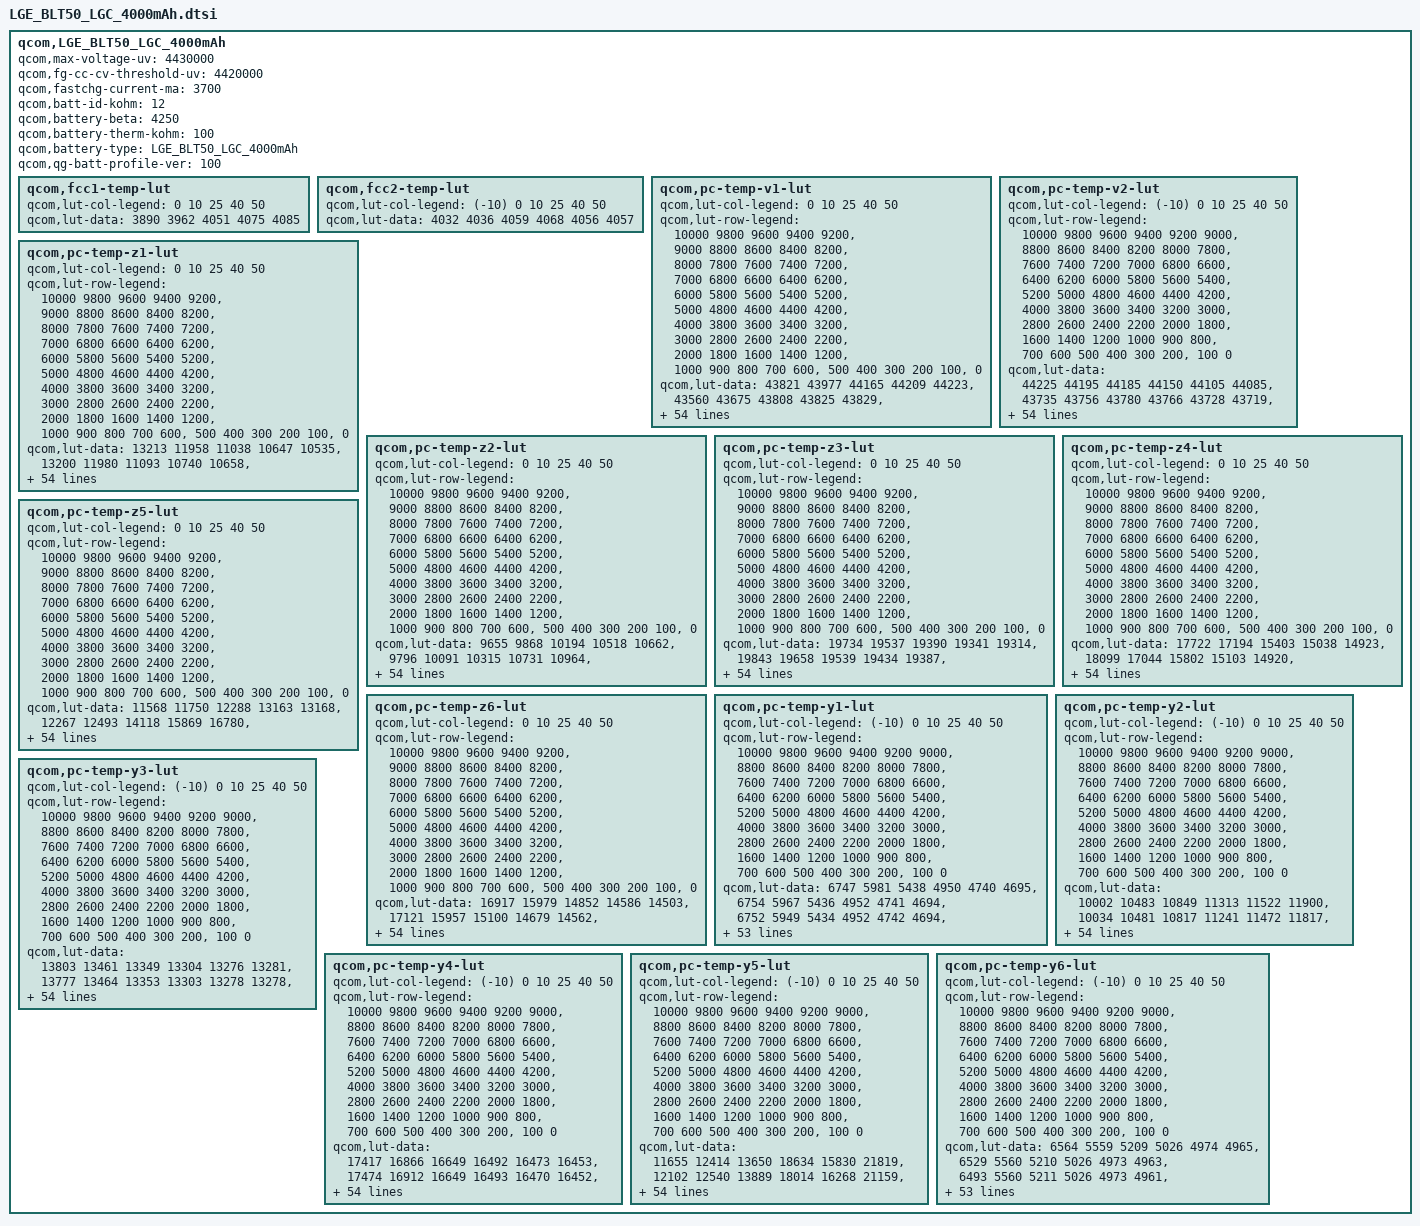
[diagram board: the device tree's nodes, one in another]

qcom,LGE_BLT50_LGC_4000mAh {
    /* 4551784_LGE_BLT50lgc_4000mAh_averaged_MasterSlave_Jun10th2020 */
    qcom,max-voltage-uv = <4430000>;
    qcom,fg-cc-cv-threshold-uv = <4420000>;
    qcom,fastchg-current-ma = <3700>;
    qcom,batt-id-kohm = <12>;
    qcom,battery-beta = <4250>;
    qcom,battery-therm-kohm = <100>;
    qcom,battery-type = "LGE_BLT50_LGC_4000mAh";
    qcom,qg-batt-profile-ver = <100>;

	qcom,fcc1-temp-lut {
		qcom,lut-col-legend = <0 10 25 40 50>;
		qcom,lut-data = <3890 3962 4051 4075 4085>;
	};

	qcom,fcc2-temp-lut {
		qcom,lut-col-legend = <(-10) 0 10 25 40 50>;
		qcom,lut-data = <4032 4036 4059 4068 4056 4057>;
	};

	qcom,pc-temp-v1-lut {
		qcom,lut-col-legend = <0 10 25 40 50>;
		qcom,lut-row-legend = <10000 9800 9600 9400 9200>,
			<9000 8800 8600 8400 8200>,
			<8000 7800 7600 7400 7200>,
			<7000 6800 6600 6400 6200>,
			<6000 5800 5600 5400 5200>,
			<5000 4800 4600 4400 4200>,
			<4000 3800 3600 3400 3200>,
			<3000 2800 2600 2400 2200>,
			<2000 1800 1600 1400 1200>,
			<1000 900 800 700 600>,
			<500 400 300 200 100>,
			<0>;
		qcom,lut-data = <43821 43977 44165 44209 44223>,
			<43560 43675 43808 43825 43829>,
			<43296 43394 43532 43538 43533>,
			<43028 43138 43284 43284 43279>,
			<42769 42897 43034 43037 43032>,
			<42517 42657 42794 42801 42799>,
			<42274 42417 42554 42567 42568>,
			<42040 42182 42313 42328 42333>,
			<41816 41953 42076 42092 42099>,
			<41598 41728 41842 41859 41866>,
			<41385 41510 41613 41629 41635>,
			<41177 41297 41391 41404 41409>,
			<40973 41088 41174 41182 41188>,
			<40774 40885 40965 40966 40973>,
			<40579 40686 40758 40759 40763>,
			<40387 40494 40557 40559 40560>,
			<40200 40307 40366 40367 40365>,
			<40028 40130 40184 40183 40180>,
			<39868 39966 40011 40007 40002>,
			<39719 39813 39851 39844 39837>,
			<39579 39664 39698 39689 39679>,
			<39446 39520 39549 39525 39512>,
			<39320 39381 39408 39352 39334>,
			<39197 39244 39243 39173 39153>,
			<39081 39110 38997 38971 38966>,
			<38971 38975 38756 38774 38783>,
			<38867 38833 38624 38643 38644>,
			<38770 38696 38535 38551 38538>,
			<38679 38572 38461 38467 38444>,
			<38594 38458 38396 38377 38352>,
			<38517 38370 38338 38293 38269>,
			<38445 38305 38279 38221 38195>,
			<38382 38253 38222 38158 38126>,
			<38325 38205 38169 38101 38065>,
			<38276 38164 38120 38052 38014>,
			<38234 38125 38074 38006 37965>,
			<38200 38090 38031 37955 37903>,
			<38163 38053 37990 37901 37830>,
			<38117 38004 37935 37836 37755>,
			<38059 37937 37854 37754 37680>,
			<37980 37854 37755 37658 37598>,
			<37849 37735 37641 37547 37489>,
			<37708 37592 37506 37415 37354>,
			<37575 37429 37346 37252 37188>,
			<37413 37278 37192 37099 37033>,
			<37270 37162 37086 37002 36942>,
			<37217 37134 37064 36980 36922>,
			<37172 37104 37042 36967 36908>,
			<37129 37077 37025 36951 36892>,
			<37081 37037 36996 36914 36851>,
			<36961 36901 36818 36708 36619>,
			<36588 36480 36406 36286 36191>,
			<35999 35902 35836 35714 35617>,
			<35199 35106 35053 34932 34834>,
			<33882 33815 33842 33728 33631>,
			<30000 30000 30000 30000 30000>;
	};

	qcom,pc-temp-v2-lut {
		qcom,lut-col-legend = <(-10) 0 10 25 40 50>;
		qcom,lut-row-legend = <10000 9800 9600 9400 9200 9000>,
			<8800 8600 8400 8200 8000 7800>,
			<7600 7400 7200 7000 6800 6600>,
			<6400 6200 6000 5800 5600 5400>,
			<5200 5000 4800 4600 4400 4200>,
			<4000 3800 3600 3400 3200 3000>,
			<2800 2600 2400 2200 2000 1800>,
			<1600 1400 1200 1000 900 800>,
			<700 600 500 400 300 200>,
			<100 0>;
		qcom,lut-data = <44225 44195 44185 44150 44105 44085>,
			<43735 43756 43780 43766 43728 43719>,
			<43316 43376 43426 43428 43395 43393>,
			<42983 43067 43131 43146 43115 43115>,
			<42716 42815 42887 42909 42879 42878>,
			<42464 42573 42650 42678 42650 42647>,
			<42210 42324 42405 42441 42414 42411>,
			<41960 42080 42163 42204 42180 42178>,
			<41700 41841 41927 41971 41948 41948>,
			<41431 41605 41694 41740 41719 41719>,
			<41178 41373 41466 41512 41493 41494>,
			<40959 41144 41244 41291 41271 41273>,
			<40748 40919 41026 41073 41053 41056>,
			<40521 40695 40816 40861 40844 40846>,
			<40281 40473 40611 40653 40641 40640>,
			<40047 40253 40401 40452 40443 40442>,
			<39820 40029 40185 40255 40249 40250>,
			<39604 39811 39968 40068 40062 40065>,
			<39400 39610 39755 39898 39889 39891>,
			<39205 39421 39545 39739 39725 39724>,
			<39029 39243 39349 39553 39555 39555>,
			<38881 39076 39165 39321 39375 39386>,
			<38736 38920 38996 39095 39190 39210>,
			<38549 38775 38843 38910 38988 39007>,
			<38330 38638 38702 38746 38780 38792>,
			<38179 38509 38573 38607 38621 38631>,
			<38093 38388 38455 38488 38503 38513>,
			<38026 38270 38347 38383 38401 38410>,
			<37959 38142 38249 38287 38307 38314>,
			<37897 38010 38157 38198 38221 38224>,
			<37837 37918 38067 38117 38143 38143>,
			<37777 37860 37976 38042 38070 38068>,
			<37718 37809 37895 37973 38000 37998>,
			<37656 37750 37826 37912 37933 37936>,
			<37595 37690 37767 37854 37867 37875>,
			<37534 37631 37717 37790 37793 37792>,
			<37474 37572 37675 37723 37712 37681>,
			<37413 37511 37629 37652 37626 37571>,
			<37348 37445 37569 37578 37536 37475>,
			<37279 37375 37498 37498 37442 37383>,
			<37212 37300 37418 37408 37350 37292>,
			<37144 37217 37323 37304 37258 37202>,
			<37067 37131 37196 37178 37141 37085>,
			<36976 37042 37051 37031 36997 36940>,
			<36874 36948 36935 36898 36857 36802>,
			<36692 36832 36845 36860 36829 36778>,
			<36615 36776 36813 36843 36817 36768>,
			<36508 36716 36771 36817 36798 36749>,
			<36357 36647 36700 36767 36761 36708>,
			<36151 36556 36565 36597 36643 36574>,
			<35839 36348 36296 36190 36295 36215>,
			<35354 35914 35809 35622 35778 35698>,
			<34586 35229 35127 34895 35133 35070>,
			<33393 34245 34106 33962 34380 34341>,
			<32071 32838 32822 32949 33297 33236>,
			<29691 29740 29526 29524 29521 29521>;
	};

	qcom,pc-temp-z1-lut {
		qcom,lut-col-legend = <0 10 25 40 50>;
		qcom,lut-row-legend = <10000 9800 9600 9400 9200>,
			<9000 8800 8600 8400 8200>,
			<8000 7800 7600 7400 7200>,
			<7000 6800 6600 6400 6200>,
			<6000 5800 5600 5400 5200>,
			<5000 4800 4600 4400 4200>,
			<4000 3800 3600 3400 3200>,
			<3000 2800 2600 2400 2200>,
			<2000 1800 1600 1400 1200>,
			<1000 900 800 700 600>,
			<500 400 300 200 100>,
			<0>;
		qcom,lut-data = <13213 11958 11038 10647 10535>,
			<13200 11980 11093 10740 10658>,
			<13194 11997 11110 10749 10665>,
			<13190 12008 11116 10754 10669>,
			<13192 12015 11111 10756 10671>,
			<13215 12014 11100 10755 10673>,
			<13238 11998 11096 10753 10673>,
			<13230 11982 11096 10752 10672>,
			<13194 11974 11096 10751 10672>,
			<13153 11966 11096 10750 10671>,
			<13099 11956 11096 10749 10671>,
			<13037 11941 11096 10749 10671>,
			<12999 11928 11097 10749 10671>,
			<12975 11924 11097 10748 10672>,
			<12950 11924 11096 10748 10672>,
			<12909 11926 11094 10748 10673>,
			<12861 11937 11094 10748 10674>,
			<12829 11950 11098 10750 10674>,
			<12807 11963 11102 10753 10675>,
			<12790 11979 11105 10756 10676>,
			<12777 11986 11107 10758 10678>,
			<12765 11988 11111 10759 10679>,
			<12759 11989 11116 10760 10680>,
			<12756 11994 11120 10761 10680>,
			<12756 12004 11121 10762 10682>,
			<12763 12014 11123 10764 10683>,
			<12776 12026 11126 10766 10685>,
			<12787 12037 11131 10769 10688>,
			<12793 12045 11137 10772 10690>,
			<12799 12051 11144 10775 10692>,
			<12806 12056 11150 10778 10694>,
			<12816 12064 11154 10781 10696>,
			<12827 12070 11157 10782 10697>,
			<12846 12072 11161 10784 10699>,
			<12868 12079 11169 10786 10701>,
			<12883 12087 11178 10789 10702>,
			<12893 12099 11187 10793 10704>,
			<12900 12115 11196 10799 10706>,
			<12902 12133 11203 10803 10708>,
			<12905 12154 11210 10805 10709>,
			<12918 12166 11216 10807 10710>,
			<12978 12171 11220 10809 10712>,
			<13013 12175 11224 10811 10714>,
			<12996 12188 11231 10812 10715>,
			<13033 12195 11239 10814 10717>,
			<12981 12184 11247 10816 10718>,
			<12988 12195 11248 10816 10719>,
			<13022 12209 11246 10816 10719>,
			<12977 12202 11251 10818 10720>,
			<12997 12191 11259 10820 10722>,
			<12988 12210 11265 10824 10725>,
			<12993 12226 11278 10830 10729>,
			<13009 12256 11307 10839 10735>,
			<13048 12265 11334 10851 10745>,
			<13048 12265 11334 10851 10745>,
			<13048 12265 11334 10851 10745>;
	};

	qcom,pc-temp-z2-lut {
		qcom,lut-col-legend = <0 10 25 40 50>;
		qcom,lut-row-legend = <10000 9800 9600 9400 9200>,
			<9000 8800 8600 8400 8200>,
			<8000 7800 7600 7400 7200>,
			<7000 6800 6600 6400 6200>,
			<6000 5800 5600 5400 5200>,
			<5000 4800 4600 4400 4200>,
			<4000 3800 3600 3400 3200>,
			<3000 2800 2600 2400 2200>,
			<2000 1800 1600 1400 1200>,
			<1000 900 800 700 600>,
			<500 400 300 200 100>,
			<0>;
		qcom,lut-data = <9655 9868 10194 10518 10662>,
			<9796 10091 10315 10731 10964>,
			<9837 10205 10326 10705 10976>,
			<9863 10199 10330 10655 10942>,
			<9887 10183 10317 10616 10925>,
			<9916 10171 10289 10579 10916>,
			<9944 10156 10282 10565 10912>,
			<9960 10142 10286 10595 10927>,
			<9973 10130 10289 10637 10947>,
			<9977 10120 10268 10656 10926>,
			<9977 10114 10232 10668 10827>,
			<9977 10112 10245 10672 10777>,
			<9976 10109 10387 10638 10814>,
			<9974 10104 10515 10605 10864>,
			<9973 10095 10562 10608 10885>,
			<9974 10084 10601 10616 10900>,
			<9976 10071 10639 10620 10919>,
			<9976 10057 10680 10627 10949>,
			<9974 10044 10704 10636 10976>,
			<9971 10031 10608 10656 10988>,
			<9971 10028 10464 10691 10996>,
			<9971 10032 10456 10752 11029>,
			<9969 10039 10483 10895 11210>,
			<9961 10050 10500 10987 11350>,
			<9950 10072 10505 10870 11250>,
			<9943 10096 10508 10678 11062>,
			<9938 10123 10508 10665 11047>,
			<9935 10149 10504 10782 11229>,
			<9935 10167 10505 10852 11350>,
			<9936 10181 10529 10839 11222>,
			<9939 10192 10558 10820 11021>,
			<9950 10200 10566 10814 10971>,
			<9963 10207 10571 10812 10980>,
			<9974 10215 10572 10815 11001>,
			<9983 10223 10567 10867 11043>,
			<9960 10233 10561 10946 11115>,
			<9758 10246 10568 11008 11248>,
			<9566 10262 10588 11067 11471>,
			<9512 10279 10610 11115 11552>,
			<9479 10301 10635 11160 11467>,
			<9497 10320 10659 11188 11380>,
			<9847 10334 10679 11184 11387>,
			<10012 10350 10696 11176 11414>,
			<9632 10370 10707 11204 11436>,
			<9499 10505 10765 11216 11456>,
			<9405 10567 10837 11192 11491>,
			<9365 10485 10806 11150 11486>,
			<9297 10398 10790 11184 11510>,
			<9303 10452 10782 11175 11562>,
			<9314 10498 10798 11254 11663>,
			<9312 10522 10927 11233 11257>,
			<9300 10370 10813 11041 11080>,
			<9343 10170 10748 10894 10983>,
			<9389 10001 10656 10777 10918>,
			<9389 10001 10656 10777 10918>,
			<9389 10001 10656 10777 10918>;
	};

	qcom,pc-temp-z3-lut {
		qcom,lut-col-legend = <0 10 25 40 50>;
		qcom,lut-row-legend = <10000 9800 9600 9400 9200>,
			<9000 8800 8600 8400 8200>,
			<8000 7800 7600 7400 7200>,
			<7000 6800 6600 6400 6200>,
			<6000 5800 5600 5400 5200>,
			<5000 4800 4600 4400 4200>,
			<4000 3800 3600 3400 3200>,
			<3000 2800 2600 2400 2200>,
			<2000 1800 1600 1400 1200>,
			<1000 900 800 700 600>,
			<500 400 300 200 100>,
			<0>;
		qcom,lut-data = <19734 19537 19390 19341 19314>,
			<19843 19658 19539 19434 19387>,
			<19906 19718 19587 19456 19412>,
			<19951 19708 19605 19468 19423>,
			<19976 19684 19605 19467 19423>,
			<19993 19673 19602 19459 19412>,
			<20003 19668 19597 19448 19399>,
			<20002 19663 19579 19435 19388>,
			<19997 19655 19558 19421 19377>,
			<19989 19646 19540 19408 19367>,
			<19978 19636 19524 19395 19358>,
			<19962 19624 19516 19385 19349>,
			<19948 19615 19513 19378 19340>,
			<19933 19613 19511 19372 19333>,
			<19919 19612 19504 19363 19330>,
			<19906 19612 19495 19354 19328>,
			<19893 19613 19489 19350 19326>,
			<19880 19616 19485 19349 19322>,
			<19865 19618 19479 19348 19319>,
			<19851 19619 19465 19348 19319>,
			<19835 19620 19448 19347 19319>,
			<19820 19623 19445 19350 19321>,
			<19808 19626 19443 19364 19332>,
			<19800 19628 19443 19375 19341>,
			<19793 19631 19454 19368 19331>,
			<19785 19634 19466 19356 19313>,
			<19778 19643 19465 19348 19314>,
			<19771 19650 19457 19341 19342>,
			<19765 19651 19448 19339 19361>,
			<19759 19649 19441 19360 19360>,
			<19754 19647 19435 19389 19359>,
			<19750 19639 19437 19391 19356>,
			<19744 19627 19443 19381 19349>,
			<19733 19618 19447 19373 19342>,
			<19713 19609 19449 19366 19336>,
			<19678 19600 19450 19361 19332>,
			<19591 19592 19448 19360 19333>,
			<19509 19584 19443 19361 19336>,
			<19469 19578 19438 19360 19337>,
			<19440 19573 19432 19360 19334>,
			<19446 19568 19428 19358 19329>,
			<19634 19561 19428 19353 19324>,
			<19726 19553 19427 19347 19319>,
			<19555 19544 19420 19345 19318>,
			<19427 19498 19403 19339 19318>,
			<19350 19470 19392 19332 19313>,
			<19338 19407 19382 19333 19311>,
			<19297 19367 19381 19325 19308>,
			<19295 19329 19365 19323 19305>,
			<19292 19321 19348 19319 19304>,
			<19291 19326 19366 19329 19326>,
			<19297 19365 19355 19339 19331>,
			<19357 19366 19372 19347 19333>,
			<19445 19370 19400 19349 19332>,
			<19445 19370 19400 19349 19332>,
			<19445 19370 19400 19349 19332>;
	};

	qcom,pc-temp-z4-lut {
		qcom,lut-col-legend = <0 10 25 40 50>;
		qcom,lut-row-legend = <10000 9800 9600 9400 9200>,
			<9000 8800 8600 8400 8200>,
			<8000 7800 7600 7400 7200>,
			<7000 6800 6600 6400 6200>,
			<6000 5800 5600 5400 5200>,
			<5000 4800 4600 4400 4200>,
			<4000 3800 3600 3400 3200>,
			<3000 2800 2600 2400 2200>,
			<2000 1800 1600 1400 1200>,
			<1000 900 800 700 600>,
			<500 400 300 200 100>,
			<0>;
		qcom,lut-data = <17722 17194 15403 15038 14923>,
			<18099 17044 15802 15103 14920>,
			<17934 16831 15540 15039 14898>,
			<17431 16511 15250 14929 14836>,
			<16982 16116 15117 14868 14797>,
			<16614 15834 15021 14826 14771>,
			<16292 15630 14946 14800 14757>,
			<16053 15472 14880 14785 14751>,
			<15859 15355 14837 14775 14748>,
			<15704 15262 14819 14767 14745>,
			<15577 15186 14807 14762 14741>,
			<15473 15121 14789 14756 14737>,
			<15390 15070 14759 14747 14732>,
			<15322 15034 14735 14739 14726>,
			<15267 15006 14724 14733 14719>,
			<15224 14982 14715 14728 14708>,
			<15187 14960 14708 14722 14700>,
			<15156 14939 14700 14713 14693>,
			<15127 14916 14695 14705 14688>,
			<15103 14892 14701 14698 14682>,
			<15083 14870 14713 14692 14676>,
			<15066 14848 14714 14691 14675>,
			<15061 14829 14712 14695 14683>,
			<15062 14815 14713 14702 14699>,
			<15065 14803 14774 14751 14744>,
			<15067 14799 14848 14823 14808>,
			<15068 14802 14855 14835 14816>,
			<15069 14807 14850 14826 14773>,
			<15070 14817 14844 14811 14733>,
			<15071 14832 14829 14768 14712>,
			<15070 14839 14809 14717 14697>,
			<15069 14836 14787 14701 14687>,
			<15068 14832 14762 14694 14680>,
			<15071 14826 14743 14690 14676>,
			<15080 14819 14729 14687 14674>,
			<15103 14811 14720 14685 14673>,
			<15197 14802 14718 14687 14680>,
			<15271 14793 14717 14695 14700>,
			<15272 14783 14718 14701 14708>,
			<15270 14771 14727 14705 14704>,
			<15244 14765 14736 14708 14698>,
			<14961 14763 14729 14705 14693>,
			<14820 14762 14719 14700 14687>,
			<14961 14749 14718 14699 14688>,
			<14959 14720 14707 14694 14684>,
			<14992 14706 14682 14676 14669>,
			<15002 14761 14676 14662 14656>,
			<15036 14799 14664 14651 14641>,
			<15029 14830 14668 14640 14629>,
			<15014 14831 14681 14643 14634>,
			<15004 14819 14681 14657 14630>,
			<15014 14801 14706 14649 14627>,
			<14998 14818 14691 14642 14627>,
			<14949 14837 14669 14643 14632>,
			<14949 14837 14669 14643 14632>,
			<14949 14837 14669 14643 14632>;
	};

	qcom,pc-temp-z5-lut {
		qcom,lut-col-legend = <0 10 25 40 50>;
		qcom,lut-row-legend = <10000 9800 9600 9400 9200>,
			<9000 8800 8600 8400 8200>,
			<8000 7800 7600 7400 7200>,
			<7000 6800 6600 6400 6200>,
			<6000 5800 5600 5400 5200>,
			<5000 4800 4600 4400 4200>,
			<4000 3800 3600 3400 3200>,
			<3000 2800 2600 2400 2200>,
			<2000 1800 1600 1400 1200>,
			<1000 900 800 700 600>,
			<500 400 300 200 100>,
			<0>;
		qcom,lut-data = <11568 11750 12288 13163 13168>,
			<12267 12493 14118 15869 16780>,
			<13157 13134 14945 16703 18566>,
			<14196 13657 15551 17917 19750>,
			<15242 14113 16152 18381 19943>,
			<16318 14575 16700 18624 19896>,
			<17358 15069 17392 18704 19806>,
			<18267 15486 18414 18631 19317>,
			<19094 15796 19024 18479 18529>,
			<19799 16043 19014 18187 17989>,
			<20400 16137 18982 17666 17554>,
			<20915 16164 19222 17400 17190>,
			<21337 16187 21028 17468 16819>,
			<21713 16196 22916 17584 16562>,
			<21990 16160 24050 17458 16661>,
			<22199 16162 25100 17125 17081>,
			<22369 16230 26189 17045 17426>,
			<22422 16349 27463 17575 17701>,
			<22418 16603 28311 18351 18016>,
			<22390 17113 26712 19022 18543>,
			<22249 17730 24245 19860 19618>,
			<21905 18773 24378 22024 21462>,
			<21485 20163 25489 29142 26167>,
			<20882 21709 27416 33936 29521>,
			<20222 23602 35382 30514 25633>,
			<19690 26084 43854 23953 18313>,
			<19209 30575 42415 20026 16769>,
			<18815 34601 34188 17169 17737>,
			<18491 35707 27956 16015 19066>,
			<18227 36285 24220 18947 20795>,
			<18053 36400 21985 23409 22923>,
			<17941 34455 22154 25372 24870>,
			<17787 31644 23300 26654 26818>,
			<17409 29977 24843 27692 28324>,
			<16761 28701 27729 28739 29590>,
			<15845 27887 30249 29599 30443>,
			<14142 27250 30982 30043 30401>,
			<12724 26791 31403 30363 29890>,
			<12230 27027 31350 30352 29049>,
			<11909 28229 29776 28486 26563>,
			<12431 29114 28422 26025 23713>,
			<20632 29334 28878 24498 22132>,
			<24459 29606 29603 23223 20955>,
			<15240 30918 27441 21794 19724>,
			<12933 29628 27083 21367 19834>,
			<12117 27026 28798 22359 20392>,
			<11868 17105 25255 24205 21493>,
			<11364 13980 25961 23459 23710>,
			<11335 12644 22767 25443 27461>,
			<11290 12453 17812 23814 24633>,
			<11304 12771 21051 20298 28116>,
			<11440 14133 17077 22407 31303>,
			<11982 13651 18916 25774 35034>,
			<12906 13423 23766 26648 33155>,
			<12906 13423 23766 26648 33155>,
			<12906 13423 23766 26648 33155>;
	};

	qcom,pc-temp-z6-lut {
		qcom,lut-col-legend = <0 10 25 40 50>;
		qcom,lut-row-legend = <10000 9800 9600 9400 9200>,
			<9000 8800 8600 8400 8200>,
			<8000 7800 7600 7400 7200>,
			<7000 6800 6600 6400 6200>,
			<6000 5800 5600 5400 5200>,
			<5000 4800 4600 4400 4200>,
			<4000 3800 3600 3400 3200>,
			<3000 2800 2600 2400 2200>,
			<2000 1800 1600 1400 1200>,
			<1000 900 800 700 600>,
			<500 400 300 200 100>,
			<0>;
		qcom,lut-data = <16917 15979 14852 14586 14503>,
			<17121 15957 15100 14679 14562>,
			<17055 15907 15012 14660 14561>,
			<16846 15781 14909 14625 14546>,
			<16652 15581 14852 14600 14531>,
			<16484 15441 14807 14578 14515>,
			<16332 15346 14767 14561 14502>,
			<16213 15270 14729 14547 14493>,
			<16115 15208 14700 14536 14486>,
			<16029 15157 14684 14525 14479>,
			<15952 15114 14671 14516 14473>,
			<15883 15076 14658 14507 14466>,
			<15823 15048 14645 14500 14459>,
			<15769 15032 14633 14492 14453>,
			<15722 15022 14623 14485 14447>,
			<15680 15014 14615 14478 14441>,
			<15643 15008 14609 14472 14436>,
			<15609 15004 14603 14468 14431>,
			<15577 14997 14599 14464 14427>,
			<15550 14991 14594 14461 14425>,
			<15528 14985 14590 14458 14422>,
			<15509 14979 14588 14459 14422>,
			<15503 14976 14587 14466 14431>,
			<15507 14975 14588 14477 14443>,
			<15513 14975 14620 14497 14460>,
			<15518 14975 14658 14519 14477>,
			<15523 14981 14661 14522 14480>,
			<15528 14991 14657 14516 14477>,
			<15533 14999 14651 14508 14471>,
			<15538 15007 14642 14502 14465>,
			<15543 15010 14631 14496 14457>,
			<15548 15006 14624 14489 14450>,
			<15551 15001 14617 14481 14443>,
			<15550 14996 14612 14475 14438>,
			<15548 14990 14609 14470 14433>,
			<15544 14985 14607 14467 14430>,
			<15533 14981 14605 14468 14433>,
			<15524 14977 14604 14471 14444>,
			<15525 14975 14604 14474 14448>,
			<15526 14974 14607 14476 14445>,
			<15530 14973 14609 14477 14440>,
			<15543 14973 14607 14474 14435>,
			<15549 14973 14603 14468 14430>,
			<15530 14967 14600 14467 14430>,
			<15473 14933 14588 14462 14428>,
			<15451 14916 14573 14450 14419>,
			<15451 14909 14567 14445 14413>,
			<15449 14906 14561 14436 14404>,
			<15446 14903 14556 14429 14398>,
			<15445 14904 14554 14430 14399>,
			<15451 14912 14565 14441 14410>,
			<15466 14935 14575 14445 14412>,
			<15501 14956 14584 14448 14415>,
			<15543 14988 14599 14452 14419>,
			<15543 14988 14599 14452 14419>,
			<15543 14988 14599 14452 14419>;
	};

	qcom,pc-temp-y1-lut {
		qcom,lut-col-legend = <(-10) 0 10 25 40 50>;
		qcom,lut-row-legend = <10000 9800 9600 9400 9200 9000>,
			<8800 8600 8400 8200 8000 7800>,
			<7600 7400 7200 7000 6800 6600>,
			<6400 6200 6000 5800 5600 5400>,
			<5200 5000 4800 4600 4400 4200>,
			<4000 3800 3600 3400 3200 3000>,
			<2800 2600 2400 2200 2000 1800>,
			<1600 1400 1200 1000 900 800>,
			<700 600 500 400 300 200>,
			<100 0>;
		qcom,lut-data = <6747 5981 5438 4950 4740 4695>,
			<6754 5967 5436 4952 4741 4694>,
			<6752 5949 5434 4952 4742 4694>,
			<6746 5931 5431 4951 4742 4693>,
			<6737 5918 5428 4949 4742 4693>,
			<6731 5913 5425 4947 4741 4692>,
			<6721 5915 5421 4943 4740 4692>,
			<6711 5918 5418 4940 4739 4692>,
			<6723 5921 5418 4937 4738 4691>,
			<6782 5925 5422 4935 4737 4690>,
			<6815 5928 5424 4933 4736 4690>,
			<6796 5929 5420 4931 4736 4689>,
			<6771 5930 5416 4929 4736 4689>,
			<6762 5930 5414 4928 4735 4689>,
			<6753 5928 5414 4927 4735 4689>,
			<6749 5928 5413 4926 4735 4689>,
			<6757 5936 5412 4926 4736 4689>,
			<6769 5944 5412 4927 4736 4690>,
			<6771 5944 5412 4929 4737 4690>,
			<6772 5936 5414 4933 4737 4691>,
			<6774 5933 5416 4935 4737 4691>,
			<6780 5934 5421 4935 4736 4691>,
			<6786 5935 5426 4935 4736 4691>,
			<6770 5935 5426 4936 4737 4691>,
			<6721 5934 5425 4939 4738 4692>,
			<6702 5934 5427 4942 4739 4692>,
			<6723 5936 5433 4944 4740 4693>,
			<6745 5940 5438 4946 4741 4693>,
			<6759 5949 5439 4950 4743 4694>,
			<6793 5966 5439 4954 4744 4695>,
			<6804 5971 5440 4955 4745 4696>,
			<6770 5956 5445 4956 4746 4697>,
			<6736 5942 5450 4957 4747 4698>,
			<6741 5939 5452 4961 4749 4699>,
			<6765 5938 5454 4966 4752 4701>,
			<6779 5937 5456 4968 4754 4702>,
			<6772 5936 5456 4970 4755 4703>,
			<6760 5934 5457 4971 4756 4704>,
			<6743 5943 5459 4974 4757 4705>,
			<6703 5961 5461 4978 4758 4705>,
			<6694 5962 5464 4981 4759 4706>,
			<6748 5937 5467 4984 4761 4707>,
			<6803 5933 5471 4986 4762 4709>,
			<6848 5955 5475 4988 4763 4710>,
			<6921 5947 5477 4994 4766 4711>,
			<6908 5960 5490 4999 4768 4712>,
			<6954 5977 5492 4999 4769 4713>,
			<7029 5963 5492 5000 4770 4713>,
			<7074 5965 5492 5008 4772 4714>,
			<7157 5975 5501 5012 4773 4715>,
			<7268 6031 5496 5017 4776 4717>,
			<7358 6081 5497 5031 4781 4721>,
			<7481 6159 5533 5053 4789 4726>,
			<7945 6315 5624 5076 4798 4733>,
			<7945 6315 5624 5076 4798 4733>,
			<7945 6315 5624 5076 4798 4733>;
	};

	qcom,pc-temp-y2-lut {
		qcom,lut-col-legend = <(-10) 0 10 25 40 50>;
		qcom,lut-row-legend = <10000 9800 9600 9400 9200 9000>,
			<8800 8600 8400 8200 8000 7800>,
			<7600 7400 7200 7000 6800 6600>,
			<6400 6200 6000 5800 5600 5400>,
			<5200 5000 4800 4600 4400 4200>,
			<4000 3800 3600 3400 3200 3000>,
			<2800 2600 2400 2200 2000 1800>,
			<1600 1400 1200 1000 900 800>,
			<700 600 500 400 300 200>,
			<100 0>;
		qcom,lut-data = <10002 10483 10849 11313 11522 11900>,
			<10034 10481 10817 11241 11472 11817>,
			<10073 10483 10786 11169 11410 11734>,
			<10119 10487 10757 11101 11346 11657>,
			<10171 10493 10732 11044 11290 11591>,
			<10227 10501 10713 11002 11253 11540>,
			<10290 10514 10696 10971 11225 11499>,
			<10358 10527 10685 10949 11204 11469>,
			<10436 10527 10684 10939 11198 11452>,
			<10532 10521 10689 10933 11193 11441>,
			<10579 10518 10695 10931 11197 11440>,
			<10582 10566 10704 10935 11226 11482>,
			<10585 10646 10718 10943 11262 11530>,
			<10605 10697 10743 10959 11283 11542>,
			<10666 10737 10784 10991 11299 11562>,
			<10715 10767 10827 11028 11322 11580>,
			<10745 10786 10875 11070 11363 11593>,
			<10764 10803 10916 11120 11420 11610>,
			<10596 10830 10939 11187 11499 11656>,
			<10011 10865 10955 11261 11604 11750>,
			<9725 10900 10975 11280 11675 11861>,
			<9713 10939 11004 11264 11725 12031>,
			<9706 10970 11034 11251 11753 12149>,
			<9695 10982 11059 11266 11698 12066>,
			<9682 10990 11081 11304 11571 11876>,
			<9674 10989 11106 11337 11534 11824>,
			<9671 10937 11134 11367 11562 11861>,
			<9668 10884 11155 11395 11608 11906>,
			<9666 10886 11166 11421 11694 11951>,
			<9665 10898 11173 11444 11824 12015>,
			<9664 10901 11172 11468 11927 12084>,
			<9663 10879 11155 11496 12018 12202>,
			<9662 10833 11136 11508 12068 12332>,
			<9662 10565 11120 11500 12074 12488>,
			<9662 10011 11102 11485 12077 12635>,
			<9661 9777 11083 11470 12069 12615>,
			<9661 9722 11063 11451 12021 12384>,
			<9661 9693 11042 11433 11963 12241>,
			<9661 9681 11022 11417 11880 12248>,
			<9660 9674 11000 11399 11796 12257>,
			<9660 9669 10973 11376 11793 12252>,
			<9660 9665 10939 11347 11839 12221>,
			<9659 9663 10885 11328 11834 12166>,
			<9658 9661 10807 11297 11776 12112>,
			<9656 9659 10750 11232 11683 12172>,
			<9655 9659 10611 11229 11679 11928>,
			<9654 9658 10656 11223 11639 11833>,
			<9653 9657 10589 11196 11675 11797>,
			<9651 9656 10236 11160 11606 11699>,
			<9650 9655 9731 11128 11519 11648>,
			<9650 9653 9680 11059 11485 11571>,
			<9650 9651 9662 10940 11402 11480>,
			<9651 9649 9655 10825 11278 11396>,
			<9653 9651 9663 10780 11286 11470>,
			<9653 9651 9663 10780 11286 11470>,
			<9653 9651 9663 10780 11286 11470>;
	};

	qcom,pc-temp-y3-lut {
		qcom,lut-col-legend = <(-10) 0 10 25 40 50>;
		qcom,lut-row-legend = <10000 9800 9600 9400 9200 9000>,
			<8800 8600 8400 8200 8000 7800>,
			<7600 7400 7200 7000 6800 6600>,
			<6400 6200 6000 5800 5600 5400>,
			<5200 5000 4800 4600 4400 4200>,
			<4000 3800 3600 3400 3200 3000>,
			<2800 2600 2400 2200 2000 1800>,
			<1600 1400 1200 1000 900 800>,
			<700 600 500 400 300 200>,
			<100 0>;
		qcom,lut-data = <13803 13461 13349 13304 13276 13281>,
			<13777 13464 13353 13303 13278 13278>,
			<13753 13467 13358 13303 13279 13276>,
			<13731 13470 13363 13303 13280 13274>,
			<13711 13473 13367 13303 13281 13274>,
			<13694 13475 13370 13304 13283 13273>,
			<13682 13476 13371 13305 13284 13274>,
			<13670 13478 13371 13307 13285 13275>,
			<13650 13477 13371 13307 13286 13276>,
			<13617 13475 13371 13308 13287 13278>,
			<13586 13472 13370 13308 13287 13280>,
			<13560 13469 13371 13312 13288 13282>,
			<13539 13465 13373 13315 13289 13284>,
			<13529 13458 13374 13314 13290 13284>,
			<13524 13445 13375 13312 13294 13285>,
			<13516 13434 13376 13311 13295 13285>,
			<13493 13428 13372 13311 13293 13283>,
			<13470 13422 13367 13312 13291 13282>,
			<13469 13414 13362 13314 13291 13282>,
			<13473 13405 13356 13318 13292 13283>,
			<13479 13397 13350 13319 13292 13283>,
			<13492 13391 13345 13314 13291 13283>,
			<13503 13385 13341 13307 13290 13283>,
			<13497 13378 13338 13303 13286 13281>,
			<13476 13369 13336 13300 13281 13275>,
			<13467 13366 13335 13298 13279 13274>,
			<13479 13366 13334 13296 13278 13274>,
			<13499 13366 13333 13296 13278 13274>,
			<13525 13363 13331 13296 13279 13273>,
			<13561 13355 13329 13297 13280 13273>,
			<13599 13352 13329 13297 13280 13273>,
			<13639 13355 13329 13297 13281 13273>,
			<13679 13358 13329 13297 13281 13274>,
			<13716 13361 13330 13297 13280 13274>,
			<13751 13365 13331 13298 13280 13275>,
			<13789 13370 13333 13298 13280 13275>,
			<13829 13385 13337 13298 13279 13273>,
			<13872 13405 13340 13298 13278 13271>,
			<13915 13428 13342 13298 13277 13271>,
			<13960 13458 13343 13298 13276 13271>,
			<14011 13495 13345 13298 13276 13271>,
			<14067 13546 13348 13299 13277 13272>,
			<14151 13613 13347 13299 13277 13273>,
			<14292 13703 13345 13299 13277 13273>,
			<14518 13791 13343 13294 13276 13270>,
			<14602 13775 13339 13298 13279 13273>,
			<14943 13888 13352 13300 13280 13277>,
			<15370 14010 13362 13304 13283 13278>,
			<16030 14138 13376 13311 13286 13281>,
			<17106 14320 13416 13313 13290 13282>,
			<19005 14748 13500 13313 13287 13281>,
			<22891 15803 13714 13321 13290 13281>,
			<31986 18618 14345 13334 13291 13283>,
			<50985 26067 16268 13360 13296 13287>,
			<50985 26067 16268 13360 13296 13287>,
			<50985 26067 16268 13360 13296 13287>;
	};

	qcom,pc-temp-y4-lut {
		qcom,lut-col-legend = <(-10) 0 10 25 40 50>;
		qcom,lut-row-legend = <10000 9800 9600 9400 9200 9000>,
			<8800 8600 8400 8200 8000 7800>,
			<7600 7400 7200 7000 6800 6600>,
			<6400 6200 6000 5800 5600 5400>,
			<5200 5000 4800 4600 4400 4200>,
			<4000 3800 3600 3400 3200 3000>,
			<2800 2600 2400 2200 2000 1800>,
			<1600 1400 1200 1000 900 800>,
			<700 600 500 400 300 200>,
			<100 0>;
		qcom,lut-data = <17417 16866 16649 16492 16473 16453>,
			<17474 16912 16649 16493 16470 16452>,
			<17508 16947 16649 16495 16465 16450>,
			<17526 16971 16649 16497 16460 16449>,
			<17532 16985 16649 16498 16457 16448>,
			<17533 16990 16649 16499 16455 16448>,
			<17492 16980 16649 16500 16455 16448>,
			<17424 16963 16649 16501 16456 16448>,
			<17386 16953 16650 16503 16457 16449>,
			<17361 16947 16656 16509 16460 16449>,
			<17346 16940 16661 16514 16463 16449>,
			<17341 16930 16665 16517 16468 16449>,
			<17336 16921 16669 16521 16473 16451>,
			<17307 16916 16675 16532 16478 16454>,
			<17217 16914 16684 16551 16481 16462>,
			<17142 16909 16687 16570 16487 16471>,
			<17099 16879 16681 16586 16501 16481>,
			<17066 16840 16670 16601 16519 16494>,
			<17044 16821 16656 16616 16539 16506>,
			<17029 16809 16635 16631 16560 16519>,
			<17006 16797 16618 16630 16567 16529>,
			<16956 16783 16604 16585 16565 16537>,
			<16893 16768 16594 16535 16561 16542>,
			<16837 16756 16588 16510 16533 16520>,
			<16781 16744 16583 16491 16480 16470>,
			<16762 16728 16579 16488 16463 16454>,
			<16770 16697 16576 16489 16463 16453>,
			<16780 16660 16574 16491 16463 16452>,
			<16785 16621 16574 16494 16466 16456>,
			<16789 16582 16575 16500 16472 16464>,
			<16794 16571 16572 16507 16481 16473>,
			<16800 16576 16553 16516 16493 16483>,
			<16807 16587 16540 16524 16503 16493>,
			<16816 16612 16541 16534 16510 16504>,
			<16829 16653 16543 16541 16515 16513>,
			<16843 16678 16548 16540 16514 16510>,
			<16859 16690 16566 16531 16501 16484>,
			<16879 16700 16584 16522 16487 16464>,
			<16906 16709 16599 16516 16474 16457>,
			<16943 16718 16611 16510 16465 16452>,
			<16976 16728 16612 16508 16465 16453>,
			<17004 16741 16611 16507 16470 16457>,
			<17040 16757 16599 16504 16471 16457>,
			<17088 16774 16581 16496 16471 16454>,
			<17117 16777 16573 16472 16448 16441>,
			<16982 16735 16581 16477 16452 16448>,
			<17098 16750 16594 16491 16463 16453>,
			<17243 16773 16630 16515 16474 16460>,
			<17482 16808 16693 16542 16481 16463>,
			<17926 16836 16769 16535 16473 16456>,
			<18930 16943 16797 16518 16461 16452>,
			<22348 17206 16828 16546 16481 16477>,
			<38880 18514 17122 16637 16541 16547>,
			<65535 28932 19781 16893 16724 16740>,
			<65535 28932 19781 16893 16724 16740>,
			<65535 28932 19781 16893 16724 16740>;
	};

	qcom,pc-temp-y5-lut {
		qcom,lut-col-legend = <(-10) 0 10 25 40 50>;
		qcom,lut-row-legend = <10000 9800 9600 9400 9200 9000>,
			<8800 8600 8400 8200 8000 7800>,
			<7600 7400 7200 7000 6800 6600>,
			<6400 6200 6000 5800 5600 5400>,
			<5200 5000 4800 4600 4400 4200>,
			<4000 3800 3600 3400 3200 3000>,
			<2800 2600 2400 2200 2000 1800>,
			<1600 1400 1200 1000 900 800>,
			<700 600 500 400 300 200>,
			<100 0>;
		qcom,lut-data = <11655 12414 13650 18634 15830 21819>,
			<12102 12540 13889 18014 16268 21159>,
			<12555 12714 14314 17319 16922 19942>,
			<13015 12931 14788 16656 17608 18569>,
			<13480 13185 15171 16129 18142 17444>,
			<13953 13470 15326 15845 18339 16969>,
			<14554 13817 15331 15782 18303 16913>,
			<15059 14181 15323 15754 18218 16880>,
			<15060 14473 15300 15528 18050 17064>,
			<14763 14729 15241 15041 17666 17889>,
			<14599 14960 15220 14836 17212 18321>,
			<14848 15171 15550 15123 16550 18703>,
			<15353 15393 16147 15444 16001 19004>,
			<16090 15670 16835 15171 16089 18488>,
			<17269 16019 17736 14320 16521 17411>,
			<17801 16378 18570 14008 16660 16371>,
			<17659 16833 19451 14406 15569 15279>,
			<17403 17192 20038 15180 14423 14493>,
			<17101 17207 19910 17284 14387 14341>,
			<16709 17129 19451 20869 14553 14269>,
			<16604 17111 19084 22295 14999 14361>,
			<18382 17401 18691 22644 17753 15872>,
			<20407 17865 18429 22792 20222 17681>,
			<19248 18258 18462 21928 20132 18733>,
			<15056 18681 18594 20082 19599 19554>,
			<12965 19441 18790 19127 19078 19789>,
			<12626 22010 19198 18607 18475 19787>,
			<12465 24301 19750 18381 18107 19714>,
			<12493 22925 20459 18719 18317 18897>,
			<12619 18949 21372 19385 18767 17471>,
			<12748 17440 22405 19829 18952 17114>,
			<12920 17458 23773 20125 19009 17169>,
			<13067 17470 24505 20557 19064 17282>,
			<13128 16562 23862 21887 19201 17721>,
			<13213 14556 22840 23452 19437 18445>,
			<13308 13894 22725 23988 19841 18988>,
			<13520 13880 23085 24254 20759 19459>,
			<13728 13874 23291 24310 21300 19747>,
			<13799 13896 22576 23128 20794 19881>,
			<13844 13945 21613 21547 19822 19962>,
			<13979 13924 21646 20932 19032 19599>,
			<14497 13661 22171 20592 18298 18366>,
			<14866 13577 21446 20428 17458 18207>,
			<15127 13630 19065 20562 17006 18411>,
			<15469 13964 17840 19658 20543 19775>,
			<14667 14153 16571 19719 20444 18731>,
			<14624 14316 17382 18530 17956 19072>,
			<14142 14352 17140 17125 16728 17685>,
			<13161 14227 15665 17214 16624 17945>,
			<12070 14839 14325 18716 19984 22358>,
			<10754 13894 14386 20595 24024 26092>,
			<9657 11905 14250 23618 26662 26513>,
			<9092 10071 12995 24657 25674 26301>,
			<8850 9085 10068 24518 25717 26087>,
			<8850 9085 10068 24518 25717 26087>,
			<8850 9085 10068 24518 25717 26087>;
	};

	qcom,pc-temp-y6-lut {
		qcom,lut-col-legend = <(-10) 0 10 25 40 50>;
		qcom,lut-row-legend = <10000 9800 9600 9400 9200 9000>,
			<8800 8600 8400 8200 8000 7800>,
			<7600 7400 7200 7000 6800 6600>,
			<6400 6200 6000 5800 5600 5400>,
			<5200 5000 4800 4600 4400 4200>,
			<4000 3800 3600 3400 3200 3000>,
			<2800 2600 2400 2200 2000 1800>,
			<1600 1400 1200 1000 900 800>,
			<700 600 500 400 300 200>,
			<100 0>;
		qcom,lut-data = <6564 5559 5209 5026 4974 4965>,
			<6529 5560 5210 5026 4973 4963>,
			<6493 5560 5211 5026 4973 4961>,
			<6457 5560 5211 5027 4973 4960>,
			<6422 5560 5211 5027 4973 4960>,
			<6386 5559 5211 5028 4974 4959>,
			<6350 5555 5210 5028 4974 4960>,
			<6314 5548 5208 5029 4975 4961>,
			<6279 5542 5207 5030 4976 4962>,
			<6244 5536 5206 5031 4978 4963>,
			<6216 5530 5206 5033 4979 4965>,
			<6198 5525 5207 5036 4981 4966>,
			<6182 5518 5208 5039 4983 4968>,
			<6162 5512 5209 5042 4985 4970>,
			<6140 5504 5211 5045 4988 4972>,
			<6119 5495 5212 5049 4992 4974>,
			<6102 5483 5208 5054 4995 4977>,
			<6087 5470 5201 5059 4998 4979>,
			<6074 5461 5193 5065 5003 4983>,
			<6062 5454 5182 5071 5010 4987>,
			<6056 5448 5174 5072 5012 4990>,
			<6054 5443 5167 5055 5010 4992>,
			<6052 5439 5162 5036 5008 4993>,
			<6043 5436 5160 5026 4997 4985>,
			<6024 5432 5158 5018 4978 4966>,
			<6017 5430 5157 5017 4972 4960>,
			<6039 5428 5156 5017 4971 4960>,
			<6074 5427 5156 5017 4971 4960>,
			<6107 5425 5156 5018 4972 4961>,
			<6143 5423 5158 5021 4975 4963>,
			<6179 5424 5158 5024 4978 4965>,
			<6214 5446 5156 5026 4982 4968>,
			<6249 5479 5155 5029 4985 4972>,
			<6282 5508 5157 5033 4987 4975>,
			<6313 5540 5163 5036 4988 4979>,
			<6346 5574 5171 5036 4988 4977>,
			<6381 5611 5184 5034 4984 4969>,
			<6418 5652 5198 5032 4979 4962>,
			<6457 5698 5211 5031 4975 4960>,
			<6499 5750 5224 5030 4972 4959>,
			<6547 5807 5238 5031 4972 4959>,
			<6604 5872 5252 5031 4974 4961>,
			<6691 5948 5263 5032 4975 4961>,
			<6848 6036 5275 5031 4975 4961>,
			<7097 6120 5287 5021 4968 4956>,
			<7176 6109 5292 5027 4972 4960>,
			<7525 6209 5333 5034 4975 4964>,
			<7948 6313 5385 5044 4980 4967>,
			<8585 6428 5453 5059 4986 4970>,
			<9604 6588 5545 5060 4986 4969>,
			<11421 7001 5677 5059 4981 4967>,
			<15379 7932 5931 5078 4989 4975>,
			<26794 10408 6577 5123 5008 4997>,
			<60928 18814 8839 5229 5065 5055>,
			<60928 18814 8839 5229 5065 5055>,
			<60928 18814 8839 5229 5065 5055>;
	};

};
